# LPC11U6x register map
File version: 0.8
LPC11U6x ARM cortex-m0+
CPU: CM0PLUS r0p1, little endian, no MPU, no FPU, 2 interrupt priority bits
Registers are 32-bit, read-write, reset 0x0 unless marked. A register's access mark holds for its fields unless they carry their own. Offsets are from the block's base; lines under a group give offsets from that group; [hi:lo] are bit positions; {n}, {i} and the like mark numbered series; 'fields as' and 'values as' point back to an identical list; <NAME> marks a mode.

## Memory map
0x40000000 I2C0 size 0xFFF — I2C-bus controller
0x40004000 WWDT size 0xFFF — Windowed Watchdog Timer (WWDT)
0x40008000 USART0 size 0xFFF
0x4000C000 CT16B0 size 0xFFF — 16-bit counter/timers CT16B0
0x40010000 CT16B1 size 0xFFF — 16-bit counter/timers CT16B1
0x40014000 CT32B0 size 0xFFF — 32-bit counter/timers CT32B0
0x40018000 CT32B1 size 0xFFF — 32-bit counter/timers CT32B1
0x4001C000 ADC size 0xFFF — 12-bit Analog-to-Digital Converter (ADC)
0x40020000 I2C1 size 0xFFF
0x40024000 RTC size 0xFFF — Real-Time Clock (RTC)
0x40028000 DMATRIGMUX size 0xFFF — DMA controller
0x40038000 PMU size 0xFFF — Power Management Unit (PMU)
0x4003C000 FLASHCTRL size 0xFFF — Flash controller
0x40040000 SSP0 size 0xFFF — SSP/SPI
0x40044000 IOCON size 0xFFF — I/O control (IOCON)
0x40048000 SYSCON size 0xFFF — System configuration (SYSCON)
0x4004C000 USART4 size 0xFFF
0x40058000 SSP1 size 0xFFF
0x4005C000 GINT0 size 0xFFF — GPIO group interrupt 0
0x40060000 GINT1 size 0xFFF
0x4006C000 USART1 size 0xFFF
0x40070000 USART2 size 0xFFF
0x40074000 USART3 size 0xFFF
0x40080000 USB size 0xFFF — USB device controller
0x50000000 CRC size 0xFFF — Cyclic Redundancy Check (CRC) engine
0x50004000 DMA size 0xFFF — DMA controller
0x5000C000 SCT0 size 0xFFF — State Configurable Timers (SCTimer/PWM)
0x5000E000 SCT1 size 0xFFF
0xA0000000 GPIO_PORT size 0x3FFF — General Purpose I/O (GPIO)
0xA0004000 PINT size 0xFFF — Pin interrupt and pattern match (PINT)

## Interrupts
{n} PIN_INT{n} (PINT) (n=0..7)
8 GINT0
9 GINT1
10 I2C1
11 USART1_4 (USART4)
12 USART2_3 (USART2)
13 SCT0_1 (SCT0)
14 SSP1
15 I2C0
16 CT16B0
17 CT16B1
18 CT32B0
19 CT32B1
20 SSP0
21 USART (USART0)
22 USB
23 USB_FIQ (USB)
24 ADC_A (ADC)
25 RTC
26 BOD_WDT (SYSCON)
27 FLASH (FLASHCTRL)
28 DMA
30 USBWAKEUP (USB)

## DMATRIGMUX — DMA controller
Base 0x40028000
{0x0+4i} DMA_ITRIG_PINMUX[{i}] (i=0..15) reset 0x1F — Trigger input select register for DMA channel 0.
  [4:0] INP_N — Trigger input number (decimal value) to DMA channel n. All other values are reserved. 0 = ADC0_SEQA_IRQ 1 = ADC0_SEQB_IRQ 2 = CT16B0_MAT0 3 = CT16B1_MAT0 4 = CT32B0_MAT0 5 = CT16B1_MAT0 6 = PINT0 ( pin interrupt 0) 7 = PINT1 (pin interrupt1 ) 8 = SCT0_DMA0 9 = SCT0_DMA1 10 = SCT1_DMA0 11 = SCT1_DMA1

## PMU — Power Management Unit (PMU)
Base 0x40038000
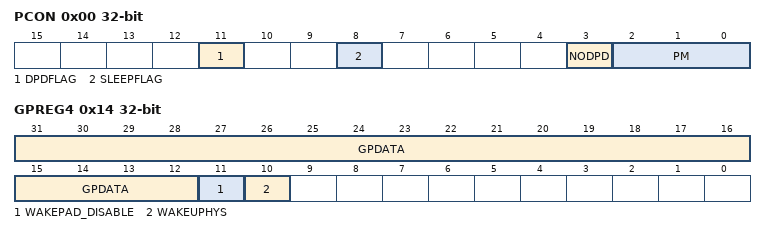
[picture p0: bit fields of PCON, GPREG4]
0x00 PCON — Power control register
  [11] DPDFLAG — Deep power-down flag
    0=NOT_DEEP_POWER_DOWN (Not Deep power-down. Read: Deep power-down mode not entered. Write: No effect.); 1=DEEP_POWER_DOWN (Deep power-down. Read: Deep power-down mode entered. Write: Clear the Deep power-down flag.)
  [8] SLEEPFLAG — Sleep mode flag
    0=ACTIVE_MODE (Active mode. Read: No power-down mode entered. Part is in Active mode. Write: No effect.); 1=LOW_POWER_MODE (Low power mode. Read: Sleep/Deep-sleep or Deep power-down mode entered. Write: Writing a 1 clears the SLEEPFLAG bit to 0.)
  [3] NODPD — A 1 in this bit prevents entry to Deep power-down mode when 0x3 is written to the PM field above, the SLEEPDEEP bit is set, and a WFI is executed. This bit is cleared only by power-on reset, so writing a one to this bit locks the part in a mode in which Deep power-down mode is blocked.
  [2:0] PM — Power mode
    0=DEFAULT (Default. The part is in active or sleep mode.); 1=DEEP_SLEEP (Deep-sleep. ARM WFI will enter Deep-sleep mode.); 2=POWER_DOWN (Power-down. ARM WFI will enter Power-down mode.); 3=DEEP_POWER_DOWN (Deep power-down. ARM WFI will enter Deep-power down mode (ARM Cortex-M0+ core powered-down).)
{0x4+4i} GPREG{i} (i=0..3) — General purpose register 0
  [31:0] GPDATA — Data retained during Deep power-down mode.
0x14 GPREG4 — Deep power down control register
  [31:12] GPDATA — Data retained during Deep power-down mode.
  [11] WAKEPAD_DISABLE — WAKEUP pin disable. Setting this bit disables the wake-up pin, so it can be used for other purposes. Never set this bit if you intend to use a pin to wake up the part from Deep power-down mode. You can only disable the wake-up pin if the RTC wake-up timer is enabled and configured. Setting this bit is not necessary if Deep power-down mode is not used.
    0=ENABLE (Enable. The wake-up function is enabled on pin PIO0_16.); 1=DISABLE (Disable. Setting this bit disables the wake-up function on pin PIO0_16.)
  [10] WAKEUPHYS — WAKEUP pin hysteresis enable
    0=DISABLE_HYSTERESIS_F (Disable Hysteresis for WAKUP pin disabled.); 1=ENABLE (Enable. Hysteresis for WAKEUP pin enabled.)
